# MIMXRT685S_cm33 register map
Vendor: nxp.com; File version: 1.0
CPU: CM33 r2p0, little endian, MPU, FPU, VTOR, 3 interrupt priority bits
Registers are 32-bit, read-write, reset 0x0 unless marked. A register's access mark holds for its fields unless they carry their own. Offsets are from the block's base; [hi:lo] are bit positions; {n}, {i} and the like mark numbered series; 'fields as' and 'values as' point back to an identical list.

## ADC0 — ADC
Base 0x4013A000
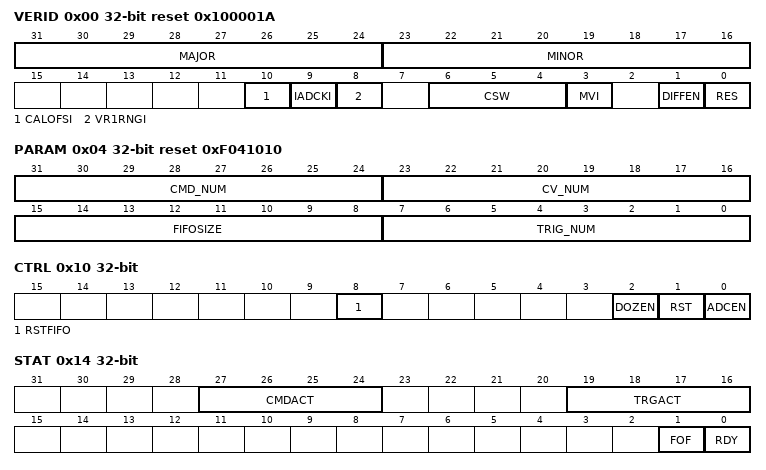
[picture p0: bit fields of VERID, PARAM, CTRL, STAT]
0x00 VERID ro reset 0x100001A — Version ID Register
  [31:24] MAJOR — Major Version Number
  [23:16] MINOR — Minor Version Number
  [10] CALOFSI — Calibration Offset Function Implemented
    0=Offset calibration and offset trimming not implemented; 1=Offset calibration and offset trimming implemented
  [9] IADCKI — Internal ADC Clock implemented
    0=Internal clock source not implemented; 1=Internal clock source (and CFG[ADCKEN]) implemented
  [8] VR1RNGI — Voltage Reference 1 Range Control Bit Implemented
    0=Range control not required. CFG[VREF1RNG] is not implemented.; 1=Range control required. CFG[VREF1RNG] is implemented.
  [6:4] CSW — Channel Scale Width
    0=Channel scaling not supported; 1=Channel scaling supported. 1-bit CSCALE control field.; 6=Channel scaling supported. 6-bit CSCALE control field.
  [3] MVI — Multi Vref Implemented
    0=Single voltage reference high (VREFH) input supported; 1=Multiple voltage reference high (VREFH) inputs supported
  [1] DIFFEN — Differential Supported
    0=Differential operation not supported; 1=Differential operation supported. CMDLa[DIFF] and CMDLa[ABSEL] control fields implemented.
  [0] RES — Resolution
    0=Up to 13-bit differential/12-bit single ended resolution supported; 1=Up to 16-bit differential/15-bit single ended resolution supported
0x04 PARAM ro reset 0xF041010 — Parameter Register
  [31:24] CMD_NUM — Command Buffer Number
  [23:16] CV_NUM — Compare Value Number
  [15:8] FIFOSIZE — Result FIFO Depth
    1=Result FIFO depth = 1 dataword; 4=Result FIFO depth = 4 datawords; 8=Result FIFO depth = 8 datawords; 16=Result FIFO depth = 16 datawords; 32=Result FIFO depth = 32 datawords; 64=Result FIFO depth = 64 datawords
  [7:0] TRIG_NUM — Trigger Number
0x10 CTRL — ADC Control Register
  [8] RSTFIFO — Reset FIFO
    0=No effect; 1=FIFO is reset
  [2] DOZEN — Doze Enable
    0=ADC is enabled in Doze mode; 1=ADC is disabled in Doze mode
  [1] RST — Software Reset
    0=ADC logic is not reset; 1=ADC logic is reset
  [0] ADCEN — ADC Enable
    0=ADC is disabled; 1=ADC is enabled
0x14 STAT — ADC Status Register
  [27:24] CMDACT ro — Command Active
    0=No command is currently in progress; 1=Command 1 currently being executed; 2=Command 2 currently being executed; 15=Command 15 currently being executed
  [19:16] TRGACT ro — Trigger Active
    0=Command (sequence) associated with Trigger 0 currently being executed; 1=Command (sequence) associated with Trigger 1 currently being executed; 15=Command (sequence) associated with Trigger 15 currently being executed
  [1] FOF write-1-clears — Result FIFO Overflow Flag
    0=No result FIFO overflow has occurred since the last time the flag was cleared; 1=At least one result FIFO overflow has occurred since the last time the flag was cleared
  [0] RDY ro — Result FIFO Ready Flag
    0=Result FIFO data level not above watermark level; 1=Result FIFO holding data above watermark level
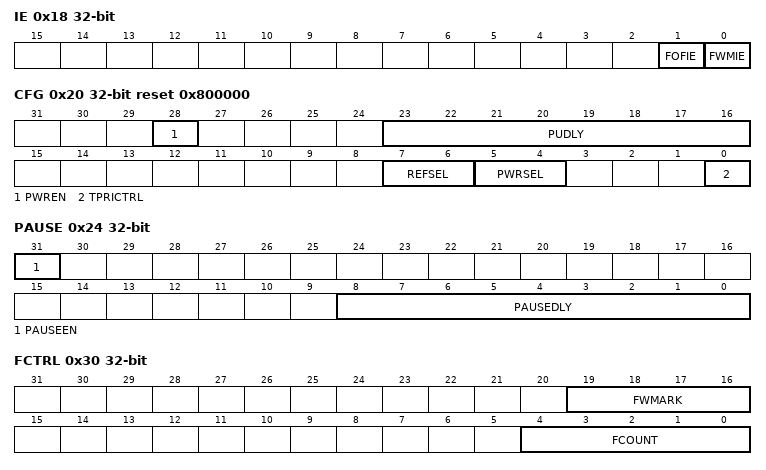
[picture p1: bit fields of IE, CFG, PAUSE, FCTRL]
0x18 IE — Interrupt Enable Register
  [1] FOFIE — Result FIFO Overflow Interrupt Enable
    0=FIFO overflow interrupts are not enabled; 1=FIFO overflow interrupts are enabled
  [0] FWMIE — FIFO Watermark Interrupt Enable
    0=FIFO watermark interrupts are not enabled; 1=FIFO watermark interrupts are enabled
0x1C DE — DMA Enable Register
  [0] FWMDE — FIFO Watermark DMA Enable
    0=DMA request disabled; 1=DMA request enabled
0x20 CFG reset 0x800000 — ADC Configuration Register
  [28] PWREN — ADC Analog Pre-Enable
    0=ADC analog circuits are only enabled while conversions are active. Performance is affected due to analog startup delays.; 1=ADC analog circuits are pre-enabled and ready to execute conversions without startup delays (at the cost of higher DC current consumption). When PWREN is set, the power up delay is enforced such that any detected trigger does not begin ADC operation until the power up delay time has passed.
  [23:16] PUDLY — Power Up Delay
  [7:6] REFSEL — Voltage Reference Selection
    0=(Default) Option 1 setting; 1=Option 2 setting; 2=Option 3 setting
  [5:4] PWRSEL — Power Configuration Select
    0=Lowest power setting; 1=Next lowest power setting; 2=PWRSEL_2; 3=Highest power setting
  [0] TPRICTRL — ADC trigger priority control
    0=If a higher priority trigger is detected during command processing, the current conversion is aborted and the new command specified by the trigger is started; 1=If a higher priority trigger is received during command processing, the current conversion is completed (including averaging iterations and compare function if enabled) and stored to the RESFIFO before the higher priority trigger/command is initiated
0x24 PAUSE — ADC Pause Register
  [31] PAUSEEN — PAUSE Option Enable
    0=Pause operation disabled; 1=Pause operation enabled
  [8:0] PAUSEDLY — Pause Delay
0x30 FCTRL — ADC FIFO Control Register
  [19:16] FWMARK — Watermark level selection
  [4:0] FCOUNT ro — Result FIFO counter
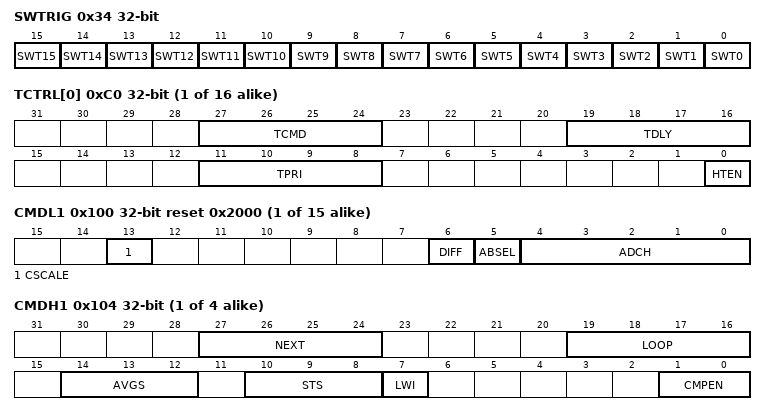
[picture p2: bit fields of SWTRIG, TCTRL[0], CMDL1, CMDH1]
0x34 SWTRIG — Software Trigger Register
  [n] SWT{n} (n=0..15) — Software trigger {n} event
    0=No trigger {n} event generated; 1=Trigger {n} event generated
{0xC0+4i} TCTRL[{i}] (i=0..15) — Trigger Control Register
  [27:24] TCMD — Trigger command select
    0=Not a valid selection from the command buffer. Trigger event is ignored.; 1=CMD1 is executed; {v}=Corresponding CMD is executed (v=2..9); 15=CMD15 is executed
  [19:16] TDLY — Trigger delay select
  [11:8] TPRI — Trigger priority setting
    0=Set to highest priority, Level 1; {v}=Set to corresponding priority level (v=1..9); 15=Set to lowest priority, Level 16
  [0] HTEN — Trigger enable
    0=Hardware trigger source disabled; 1=Hardware trigger source enabled
{0xF8+8i} CMDL{i} reset 0x2000 (i=1..15) — ADC Command Low Buffer Register
  [13] CSCALE — Channel Scale
    0=Scale selected analog channel (Factor of 30/64); 1=(Default) Full scale (Factor of 1)
  [6] DIFF — Differential Mode Enable
    0=Single-ended mode; 1=Differential mode
  [5] ABSEL — A-side vs. B-side Select
    0=When DIFF=0b0, the associated A-side channel is converted as single-ended. When DIFF=0b1, the ADC result is (CHnA-CHnB).; 1=When DIFF=0b0, the associated B-side channel is converted as single-ended. When DIFF=0b1, the ADC result is (CHnB-CHnA).
  [4:0] ADCH — Input channel select
    {v}=Select CH{v}A or CH{v}B or CH{v}A/CH{v}B pair (v=0..3); {v}=Select corresponding channel CHnA or CHnB or CHnA/CHnB pair (v=4..9); 30=Select CH30A or CH30B or CH30A/CH30B pair; 31=Select CH31A or CH31B or CH31A/CH31B pair
{0xFC+8i} CMDH{i} (i=1..4) — ADC Command High Buffer Register
  [27:24] NEXT — Next Command Select
    0=No next command defined. Terminate conversions at completion of current command. If lower priority trigger pending, begin command associated with lower priority trigger.; 1=Select CMD1 command buffer register as next command; {v}=Select corresponding CMD command buffer register as next command (v=2..9); 15=Select CMD15 command buffer register as next command
  [19:16] LOOP — Loop Count Select
    0=Looping not enabled. Command executes 1 time.; 1=Loop 1 time. Command executes 2 times.; 2=Loop 2 times. Command executes 3 times.; {v}=Loop corresponding number of times. Command executes LOOP+1 times. (v=3..9); 15=Loop 15 times. Command executes 16 times.
  [14:12] AVGS — Hardware Average Select
    0=Single conversion; 1=2 conversions averaged; 2=4 conversions averaged; 3=8 conversions averaged; 4=16 conversions averaged; 5=32 conversions averaged; 6=64 conversions averaged; 7=128 conversions averaged
  [10:8] STS — Sample Time Select
    0=Minimum sample time of 3 ADCK cycles; 1=3 + 2^1 ADCK cycles; 5 ADCK cycles total sample time; 2=3 + 2^2 ADCK cycles; 7 ADCK cycles total sample time; 3=3 + 2^3 ADCK cycles; 11 ADCK cycles total sample time; 4=3 + 2^4 ADCK cycles; 19 ADCK cycles total sample time; 5=3 + 2^5 ADCK cycles; 35 ADCK cycles total sample time; 6=3 + 2^6 ADCK cycles; 67 ADCK cycles total sample time; 7=3 + 2^7 ADCK cycles; 131 ADCK cycles total sample time
  [7] LWI — Loop with Increment
    0=Auto channel increment disabled; 1=Auto channel increment enabled
  [1:0] CMPEN — Compare Function Enable
    0=Compare disabled; 2=Compare enabled. Store on true.; 3=Compare enabled. Repeat channel acquisition (sample/convert/compare) until true.
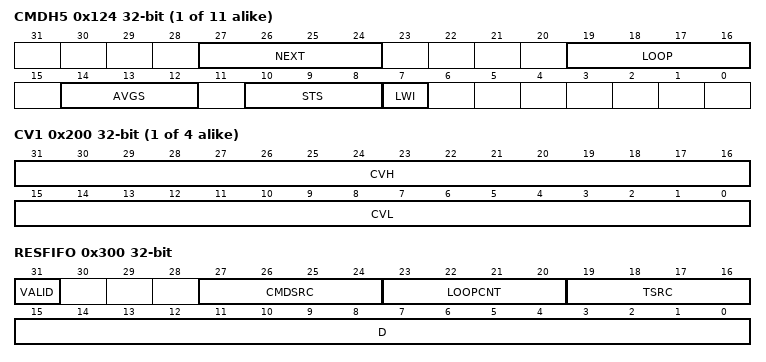
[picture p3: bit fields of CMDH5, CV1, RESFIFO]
{0xFC+8i} CMDH{i} (i=5..15) — ADC Command High Buffer Register
  [27:24] NEXT — Next Command Select
    values as CMDH1.NEXT
  [19:16] LOOP — Loop Count Select
    values as CMDH1.LOOP
  [14:12] AVGS — Hardware Average Select
    values as CMDH1.AVGS
  [10:8] STS — Sample Time Select
    values as CMDH1.STS
  [7] LWI — Loop with Increment
    values as CMDH1.LWI
{0x1FC+4i} CV{i} (i=1..4) — Compare Value Register
  [31:16] CVH — Compare Value High.
  [15:0] CVL — Compare Value Low.
0x300 RESFIFO ro — ADC Data Result FIFO Register
  [31] VALID — FIFO entry is valid
    0=FIFO is empty. Discard any read from RESFIFO.; 1=FIFO record read from RESFIFO is valid
  [27:24] CMDSRC — Command Buffer Source
    0=Not a valid value CMDSRC value for a dataword in RESFIFO. 0x0 is only found in initial FIFO state prior to an ADC conversion result dataword being stored to a RESFIFO buffer.; 1=CMD1 buffer used as control settings for this conversion; {v}=Corresponding command buffer used as control settings for this conversion (v=2..9); 15=CMD15 buffer used as control settings for this conversion
  [23:20] LOOPCNT — Loop count value
    0=Result is from initial conversion in command; 1=Result is from second conversion in command; {v}=Result is from LOOPCNT+1 conversion in command (v=2..9); 15=Result is from 16th conversion in command
  [19:16] TSRC — Trigger Source
    0=Trigger source 0 initiated this conversion; 1=Trigger source 1 initiated this conversion; {v}=Corresponding trigger source initiated this conversion (v=2..9); 15=Trigger source 15 initiated this conversion
  [15:0] D — Data result
